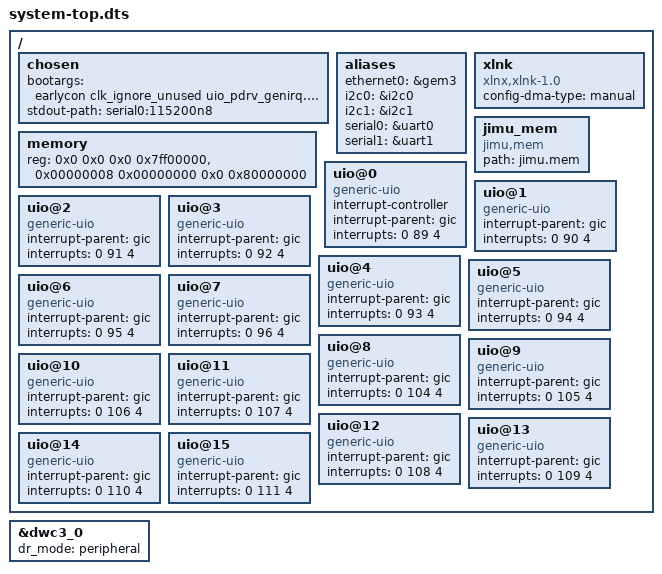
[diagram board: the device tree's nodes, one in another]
/*
 * CAUTION: This file is automatically generated by Xilinx.
 * Version: XSCT 2018.3.1
 * Today is: Wed Sep 25 10:05:39 2019
 */


/dts-v1/;
/include/ "zynqmp.dtsi"
/include/ "zynqmp-clk-ccf.dtsi"
/include/ "zcu102-rev1.0.dtsi"
/include/ "pl.dtsi"
/include/ "pcw.dtsi"
/ {
	chosen {
		bootargs = "earlycon clk_ignore_unused uio_pdrv_genirq.of_id=generic-uio cma=256m";
		stdout-path = "serial0:115200n8";
	};
	aliases {
		ethernet0 = &gem3;
		i2c0 = &i2c0;
		i2c1 = &i2c1;
		serial0 = &uart0;
		serial1 = &uart1;
	};
	memory {
		device_type = "memory";
		reg = <0x0 0x0 0x0 0x7ff00000>, <0x00000008 0x00000000 0x0 0x80000000>;
	};
	
	
	/* ---------------------------------------  lxn added  --------------------------------*/
	xlnk {
		compatible = "xlnx,xlnk-1.0";
		config-dma-type = "manual";  /* "manual" or "standard" */
	};
	
	jimu_mem {     /* jimu_mem.ko  */
		compatible = "jimu,mem";
		path = "jimu.mem";
	};
	
	uio@0 {  
		compatible = "generic-uio";
		status = "okay";
		interrupt-controller;
		interrupt-parent = <&gic>;
		interrupts = <0 89 4>;
	};
	uio@1 {  
		compatible = "generic-uio";
		status = "okay";
		interrupt-parent = <&gic>;
		interrupts = <0 90 4>;
	};
	uio@2 {  
		compatible = "generic-uio";
		status = "okay";
		interrupt-parent = <&gic>;
		interrupts = <0 91 4>;
	};
	uio@3 {  
		compatible = "generic-uio";
		status = "okay";
		interrupt-parent = <&gic>;
		interrupts = <0 92 4>;
	};
	uio@4 {  
		compatible = "generic-uio";
		status = "okay";
		interrupt-parent = <&gic>;
		interrupts = <0 93 4>;
	};
	uio@5 {  
		compatible = "generic-uio";
		status = "okay";
		interrupt-parent = <&gic>;
		interrupts = <0 94 4>;
	};
	uio@6 {  
		compatible = "generic-uio";
		status = "okay";
		interrupt-parent = <&gic>;
		interrupts = <0 95 4>;
	};
	uio@7 {  
		compatible = "generic-uio";
		status = "okay";
		interrupt-parent = <&gic>;
		interrupts = <0 96 4>;
	};
	
	uio@8 {  
		compatible = "generic-uio";
		status = "okay";
		interrupt-parent = <&gic>;
		interrupts = <0 104 4>;
	};
	uio@9 {  
		compatible = "generic-uio";
		status = "okay";
		interrupt-parent = <&gic>;
		interrupts = <0 105 4>;
	};
	uio@10 {  
		compatible = "generic-uio";
		status = "okay";
		interrupt-parent = <&gic>;
		interrupts = <0 106 4>;
	};
	uio@11 {  
		compatible = "generic-uio";
		status = "okay";
		interrupt-parent = <&gic>;
		interrupts = <0 107 4>;
	};
	uio@12 {  
		compatible = "generic-uio";
		status = "okay";
		interrupt-parent = <&gic>;
		interrupts = <0 108 4>;
	};
	uio@13 {  
		compatible = "generic-uio";
		status = "okay";
		interrupt-parent = <&gic>;
		interrupts = <0 109 4>;
	};
	uio@14 {  
		compatible = "generic-uio";
		status = "okay";
		interrupt-parent = <&gic>;
		interrupts = <0 110 4>;
	};
	uio@15 {  
		compatible = "generic-uio";
		status = "okay";
		interrupt-parent = <&gic>;
		interrupts = <0 111 4>;
	};
};

&dwc3_0 {
    status = "okay";
    dr_mode = "peripheral";
};


